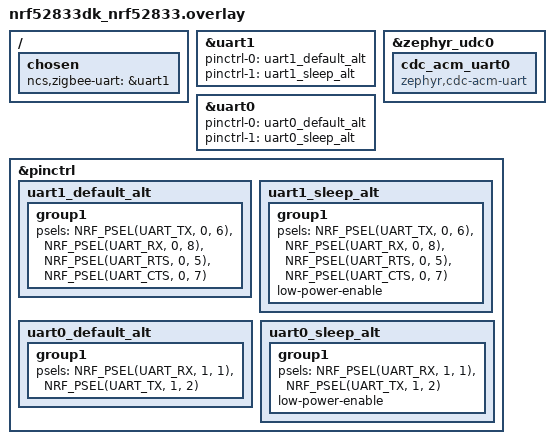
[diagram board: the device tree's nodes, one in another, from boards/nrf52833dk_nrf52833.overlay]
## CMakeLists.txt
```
#
# Copyright (c) 2024 Nordic Semiconductor ASA
#
# SPDX-License-Identifier: LicenseRef-Nordic-5-Clause
#

cmake_minimum_required(VERSION 3.20.0)

find_package(Zephyr REQUIRED HINTS $ENV{ZEPHYR_BASE})

project("ZBOSS NCP SoC firmware")

# NORDIC SDK APP START
target_sources(app PRIVATE
  src/main.c
  src/zboss_mem_globals.c
)
# NORDIC SDK APP END

if(CONFIG_LTO)
	set_source_files_properties(
		src/zboss_mem_globals.c
		PROPERTIES COMPILE_OPTIONS -fno-lto
	)
endif()
```

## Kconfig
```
#
# Copyright (c) 2025 Nordic Semiconductor ASA
#
# SPDX-License-Identifier: LicenseRef-Nordic-5-Clause
#

source "Kconfig.zephyr"

menuconfig ZIGBEE_NCP_USB
       bool "USB support for Zigbee NCP"
       select USB_DEVICE_STACK_NEXT
       select USBD_CDC_ACM_CLASS
       select UART_LINE_CTRL
       help
         Enable USB CDC ACM support for Zigbee NCP interface.
         This allows using the NCP over USB instead of UART.
         This uses the new USB device stack and is incompatible with
         the legacy USB_DEVICE_STACK option.

if ZIGBEE_NCP_USB

config ZIGBEE_NCP_USB_VID
       hex "USB Vendor ID"
       default 0x2fe3
       help
         USB Vendor ID for the Zigbee NCP device.
         Default uses Zephyr project VID (for samples only).

config ZIGBEE_NCP_USB_PID
       hex "USB Product ID"
       default 0x0001
       help
         USB Product ID for the Zigbee NCP device.

config ZIGBEE_NCP_USB_MAX_POWER
       int "USB device max power consumption (mA)"
       default 100
       range 2 500
       help
         Maximum power consumption of the USB device in milliamperes.

config ZIGBEE_NCP_USB_MANUFACTURER
       string "USB device manufacturer string"
       default "Nordic Semiconductor ASA"
       help
         USB device manufacturer string descriptor.

config ZIGBEE_NCP_USB_PRODUCT
       string "USB device product string"
       default "Zigbee NCP"
       help
         USB device product string descriptor.

endif # ZIGBEE_NCP_USB
```

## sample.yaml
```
# KRKNWK-22663: Twister scenarios are skipped while NCP libncp-dev libraries are
# not shipped. Builds fail at CMake with an explicit error.
sample:
  description: Zigbee network co-processor
  name: Zigbee NCP
common:
  tags:
    - ci_build
    - smoke
    - sysbuild
    - ci_samples_zigbee
tests:
  sample.zigbee.ncp:
    skip: true
    sysbuild: true
    build_only: true
    integration_platforms:
      - nrf52833dk/nrf52833
      - nrf52840dk/nrf52840
      - nrf54l15dk/nrf54l05/cpuapp
    platform_allow:
      - nrf52833dk/nrf52833
      - nrf52840dk/nrf52840
      - nrf5340dk/nrf5340/cpuapp
      - nrf54l15dk/nrf54l05/cpuapp
      - nrf54l15dk/nrf54l10/cpuapp
      - nrf54l15dk/nrf54l15/cpuapp
      - nrf54lm20dk/nrf54lm20a/cpuapp
      - nrf54lm20dk/nrf54lm20b/cpuapp
  sample.zigbee.ncp.usb:
    skip: true
    sysbuild: true
    build_only: true
    integration_platforms:
      - nrf52833dk/nrf52833
      - nrf52840dk/nrf52840
    platform_allow:
      - nrf52833dk/nrf52833
      - nrf52840dk/nrf52840
      - nrf5340dk/nrf5340/cpuapp
      - nrf54lm20dk/nrf54lm20a/cpuapp
      - nrf54lm20dk/nrf54lm20b/cpuapp
    extra_args:
      - FILE_SUFFIX=usb
  sample.zigbee.ncp.dongle:
    skip: true
    sysbuild: true
    build_only: true
    integration_platforms:
      - nrf52840dongle/nrf52840
    platform_allow:
      - nrf52840dongle/nrf52840
    extra_args:
      - FILE_SUFFIX=dongle
```

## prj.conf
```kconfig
#
# Copyright (c) 2024 Nordic Semiconductor ASA
#
# SPDX-License-Identifier: LicenseRef-Nordic-5-Clause
#

CONFIG_NCS_SAMPLES_DEFAULTS=y

CONFIG_ZIGBEE_ADD_ON=y

# Add libncp-dev library
CONFIG_ZIGBEE_LIBRARY_NCP_DEV=y

CONFIG_ZIGBEE_HAVE_SERIAL=y
CONFIG_ZIGBEE_HAVE_ASYNC_SERIAL=y
CONFIG_ZIGBEE_UART_RX_BUF_LEN=256
CONFIG_ZIGBEE_UART_TX_TIMEOUT=1000
CONFIG_ZIGBEE_UART_RX_TIMEOUT=1000

CONFIG_ZIGBEE_USE_LEDS=y
CONFIG_ZIGBEE_USE_BUTTONS=y
CONFIG_ZIGBEE_TIME_KTIMER=y

CONFIG_ZIGBEE_ROLE_COORDINATOR=y

CONFIG_HEAP_MEM_POOL_SIZE=2048

CONFIG_MAIN_THREAD_PRIORITY=7
# Networking
CONFIG_NET_IPV6=n
CONFIG_NET_IP_ADDR_CHECK=n
CONFIG_NET_UDP=n
```

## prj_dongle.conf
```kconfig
#
# Copyright (c) 2024 Nordic Semiconductor ASA
#
# SPDX-License-Identifier: LicenseRef-Nordic-5-Clause
#

# The NCP transport is a CDC ACM port, so the sample holds the stack until the host
# raises DTR. Boards turn line control on for their shell builds only.
CONFIG_UART_LINE_CTRL=y
CONFIG_ZIGBEE_UART_SUPPORTS_FLOW_CONTROL=y

# Configure NCP sample to print ZBOSS stack logs in binary format using uart1 device
# CONFIG_ZBOSS_TRACE_BINARY_LOGGING=y

#### Use this configuration to print ZBOSS stack logs in binary format using USB cdc_acm_uart1 device
# CONFIG_ZBOSS_TRACE_BINARY_LOGGING=y
# CONFIG_ZBOSS_TRACE_USB_CDC_LOGGING=y
# The second instance, cdc_acm_uart1, comes from the board overlay. See README.
####


# Use new USB stack with CDC ACM initialized at boot
CONFIG_USB_DEVICE_STACK_NEXT=y
CONFIG_CDC_ACM_SERIAL_INITIALIZE_AT_BOOT=y
CONFIG_CDC_ACM_SERIAL_VID=0x1915
CONFIG_CDC_ACM_SERIAL_PID=0x0001
CONFIG_CDC_ACM_SERIAL_MANUFACTURER_STRING="Nordic Semiconductor ASA"
CONFIG_CDC_ACM_SERIAL_PRODUCT_STRING="Zigbee NCP"

CONFIG_USBD_LOG_LEVEL_WRN=y
CONFIG_UDC_DRIVER_LOG_LEVEL_WRN=y
CONFIG_USBD_CDC_ACM_LOG_LEVEL_ERR=y

# Those settings below are common with prj.conf

CONFIG_NCS_SAMPLES_DEFAULTS=y

CONFIG_ZIGBEE_ADD_ON=y

# Add libncp-dev library
CONFIG_ZIGBEE_LIBRARY_NCP_DEV=y

CONFIG_ZIGBEE_HAVE_SERIAL=y
CONFIG_ZIGBEE_HAVE_ASYNC_SERIAL=y
CONFIG_ZIGBEE_UART_RX_BUF_LEN=256
CONFIG_ZIGBEE_UART_TX_TIMEOUT=1000
CONFIG_ZIGBEE_UART_RX_TIMEOUT=1000

CONFIG_ZIGBEE_USE_LEDS=y
CONFIG_ZIGBEE_USE_BUTTONS=y
CONFIG_ZIGBEE_TIME_KTIMER=y

CONFIG_ZIGBEE_ROLE_COORDINATOR=y

CONFIG_HEAP_MEM_POOL_SIZE=2048

CONFIG_MAIN_THREAD_PRIORITY=7
# Networking
CONFIG_NET_IPV6=n
CONFIG_NET_IP_ADDR_CHECK=n
CONFIG_NET_UDP=n
```

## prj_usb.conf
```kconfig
#
# Copyright (c) 2021 Nordic Semiconductor ASA
#
# SPDX-License-Identifier: LicenseRef-Nordic-5-Clause
#

# The NCP transport is a CDC ACM port, so the sample holds the stack until the host
# raises DTR. Boards turn line control on for their shell builds only.
CONFIG_UART_LINE_CTRL=y
CONFIG_ZIGBEE_UART_SUPPORTS_FLOW_CONTROL=y

# Configure NCP sample to print ZBOSS stack logs in binary format using uart1 device
# CONFIG_ZBOSS_TRACE_BINARY_LOGGING=y

#### Use this configuration to print ZBOSS stack logs in binary format using USB cdc_acm_uart1 device
# CONFIG_ZBOSS_TRACE_BINARY_LOGGING=y
# CONFIG_ZBOSS_TRACE_USB_CDC_LOGGING=y
# The second instance, cdc_acm_uart1, comes from the board overlay. See README.
####

# Use new USB stack with CDC ACM initialized at boot
CONFIG_USB_DEVICE_STACK_NEXT=y
CONFIG_CDC_ACM_SERIAL_INITIALIZE_AT_BOOT=y
CONFIG_CDC_ACM_SERIAL_VID=0x1915
CONFIG_CDC_ACM_SERIAL_PID=0x0001
CONFIG_CDC_ACM_SERIAL_MANUFACTURER_STRING="Nordic Semiconductor ASA"
CONFIG_CDC_ACM_SERIAL_PRODUCT_STRING="Zigbee NCP"

CONFIG_USBD_LOG_LEVEL_WRN=y
CONFIG_UDC_DRIVER_LOG_LEVEL_WRN=y
CONFIG_USBD_CDC_ACM_LOG_LEVEL_ERR=y

# Those settings below are common with prj.conf

CONFIG_NCS_SAMPLES_DEFAULTS=y

CONFIG_ZIGBEE_ADD_ON=y

# Add libncp-dev library
CONFIG_ZIGBEE_LIBRARY_NCP_DEV=y

CONFIG_ZIGBEE_HAVE_SERIAL=y
CONFIG_ZIGBEE_HAVE_ASYNC_SERIAL=y
CONFIG_ZIGBEE_UART_RX_BUF_LEN=256
CONFIG_ZIGBEE_UART_TX_TIMEOUT=1000
CONFIG_ZIGBEE_UART_RX_TIMEOUT=1000

CONFIG_ZIGBEE_USE_LEDS=y
CONFIG_ZIGBEE_USE_BUTTONS=y
CONFIG_ZIGBEE_TIME_KTIMER=y

CONFIG_ZIGBEE_ROLE_COORDINATOR=y

CONFIG_HEAP_MEM_POOL_SIZE=2048

CONFIG_MAIN_THREAD_PRIORITY=7
# Networking
CONFIG_NET_IPV6=n
CONFIG_NET_IP_ADDR_CHECK=n
CONFIG_NET_UDP=n
```

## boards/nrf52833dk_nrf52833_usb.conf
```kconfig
#
# Copyright (c) 2026 Nordic Semiconductor ASA
#
# SPDX-License-Identifier: LicenseRef-Nordic-5-Clause
#

# Enable MCUBoot
CONFIG_BOOTLOADER_MCUBOOT=y
```

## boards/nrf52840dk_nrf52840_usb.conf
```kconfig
#
# Copyright (c) 2025 Nordic Semiconductor ASA
#
# SPDX-License-Identifier: LicenseRef-Nordic-5-Clause
#

# Enable MCUBoot
CONFIG_BOOTLOADER_MCUBOOT=y

# Enable nRF ECB driver
CONFIG_CRYPTO=y
CONFIG_CRYPTO_NRF_ECB=y
CONFIG_CRYPTO_INIT_PRIORITY=80
```

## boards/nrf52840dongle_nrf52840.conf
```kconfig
#
# Copyright (c) 2025 Nordic Semiconductor ASA
#
# SPDX-License-Identifier: LicenseRef-Nordic-5-Clause
#

# Inform application that CDC ACM requires the line control signals to be configured.
CONFIG_ZIGBEE_UART_SUPPORTS_FLOW_CONTROL=y

# Configure NCP sample to print ZBOSS stack logs in binary format using uart1 device
# CONFIG_ZBOSS_TRACE_BINARY_LOGGING=y

#### Use this configuration to print ZBOSS stack logs in binary format using USB cdc_acm_uart1 device
# CONFIG_ZBOSS_TRACE_BINARY_LOGGING=y
# CONFIG_ZBOSS_TRACE_USB_CDC_LOGGING=y
# The second instance, cdc_acm_uart1, comes from the board overlay. See README.
####
```

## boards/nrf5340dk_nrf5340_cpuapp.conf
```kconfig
#
# Copyright (c) 2025 Nordic Semiconductor ASA
#
# SPDX-License-Identifier: LicenseRef-Nordic-5-Clause
#

CONFIG_NRF53_UPGRADE_NETWORK_CORE=n
```

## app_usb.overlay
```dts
/*
 * Copyright (c) 2026 Nordic Semiconductor ASA
 *
 * SPDX-License-Identifier: LicenseRef-Nordic-5-Clause
 */

&zephyr_udc0 {
	cdc_acm_uart0: cdc_acm_uart {
		compatible = "zephyr,cdc-acm-uart";
	};
};

/ {
	chosen {
		ncs,zigbee-uart = &cdc_acm_uart0;
	};
};
```

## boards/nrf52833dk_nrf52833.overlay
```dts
/*
 * Copyright (c) 2026 Nordic Semiconductor ASA
 *
 * SPDX-License-Identifier: LicenseRef-Nordic-5-Clause
 */

#include <nrf52833_partitions.dtsi>

&uart1 {
	status = "okay";
	pinctrl-0 = <&uart1_default_alt>;
	pinctrl-1 = <&uart1_sleep_alt>;
	pinctrl-names = "default", "sleep";
};

&uart0 {
	pinctrl-0 = <&uart0_default_alt>;
	pinctrl-1 = <&uart0_sleep_alt>;
	pinctrl-names = "default", "sleep";
};

&zephyr_udc0 {
	cdc_acm_uart0: cdc_acm_uart0 {
		compatible = "zephyr,cdc-acm-uart";
	};
};

&pinctrl {
	uart1_default_alt: uart1_default_alt {
		group1 {
			psels = <NRF_PSEL(UART_TX, 0, 6)>,
				<NRF_PSEL(UART_RX, 0, 8)>,
				<NRF_PSEL(UART_RTS, 0, 5)>,
				<NRF_PSEL(UART_CTS, 0, 7)>;
		};
	};

	uart1_sleep_alt: uart1_sleep_alt {
		group1 {
			psels = <NRF_PSEL(UART_TX, 0, 6)>,
				<NRF_PSEL(UART_RX, 0, 8)>,
				<NRF_PSEL(UART_RTS, 0, 5)>,
				<NRF_PSEL(UART_CTS, 0, 7)>;
			low-power-enable;
		};
	};

	uart0_default_alt: uart0_default_alt {
		group1 {
			psels = <NRF_PSEL(UART_RX, 1, 1)>,
				<NRF_PSEL(UART_TX, 1, 2)>;
		};
	};

	uart0_sleep_alt: uart0_sleep_alt {
		group1 {
			psels = <NRF_PSEL(UART_RX, 1, 1)>,
				<NRF_PSEL(UART_TX, 1, 2)>;
			low-power-enable;
		};
	};
};

/ {
	chosen {
		ncs,zigbee-uart = &uart1;
	};
};
```

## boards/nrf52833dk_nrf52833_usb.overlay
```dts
/*
 * Copyright (c) 2026 Nordic Semiconductor ASA
 *
 * SPDX-License-Identifier: LicenseRef-Nordic-5-Clause
 */

#include <nrf52833_partitions.dtsi>
#include <mcuboot_usb_transport/nrf52833_partitions.dtsi>

&zephyr_udc0 {
	cdc_acm_uart0: cdc_acm_uart0 {
		compatible = "zephyr,cdc-acm-uart";
	};
};

/ {
	chosen {
		ncs,zigbee-uart = &cdc_acm_uart0;
	};
};
```

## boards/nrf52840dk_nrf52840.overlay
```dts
/*
 * Copyright (c) 2025 Nordic Semiconductor ASA
 *
 * SPDX-License-Identifier: LicenseRef-Nordic-5-Clause
 */

#include <nrf52840_partitions.dtsi>

&uart1 {
	pinctrl-0 = <&uart1_default_alt>;
	pinctrl-1 = <&uart1_sleep_alt>;
	pinctrl-names = "default", "sleep";
	status = "okay";
};

&uart0 {
	pinctrl-0 = <&uart0_default_alt>;
	pinctrl-1 = <&uart0_sleep_alt>;
	pinctrl-names = "default", "sleep";
};

&zephyr_udc0 {
	cdc_acm_uart0: cdc_acm_uart0 {
		compatible = "zephyr,cdc-acm-uart";
	};
};

&pinctrl {
	uart1_default_alt: uart1_default_alt {
		group1 {
			psels = <NRF_PSEL(UART_TX, 0, 6)>,
				<NRF_PSEL(UART_RX, 0, 8)>,
				<NRF_PSEL(UART_RTS, 0, 5)>,
				<NRF_PSEL(UART_CTS, 0, 7)>;
		};
	};

	uart1_sleep_alt: uart1_sleep_alt {
		group1 {
			psels = <NRF_PSEL(UART_TX, 0, 6)>,
				<NRF_PSEL(UART_RX, 0, 8)>,
				<NRF_PSEL(UART_RTS, 0, 5)>,
				<NRF_PSEL(UART_CTS, 0, 7)>;
			low-power-enable;
		};
	};

	uart0_default_alt: uart0_default_alt {
		group1 {
			psels = <NRF_PSEL(UART_RX, 1, 1)>,
				<NRF_PSEL(UART_TX, 1, 2)>;
		};
	};

	uart0_sleep_alt: uart0_sleep_alt {
		group1 {
			psels = <NRF_PSEL(UART_RX, 1, 1)>,
				<NRF_PSEL(UART_TX, 1, 2)>;
			low-power-enable;
		};
	};
};

/ {
	chosen {
		ncs,zigbee-uart = &uart1;
	};
};
```

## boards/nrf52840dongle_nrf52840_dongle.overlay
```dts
/*
 * Copyright (c) 2025 Nordic Semiconductor ASA
 *
 * SPDX-License-Identifier: LicenseRef-Nordic-5-Clause
 */

#include <nrf52840dongle_partitions.dtsi>

/ {
	chosen {
		ncs,zigbee-uart = &board_cdc_acm_uart;
	};

	buttons {
		compatible = "gpio-keys";

		rst_button0: rst_button_0 {
			gpios = <&gpio0 19 (GPIO_PULL_UP | GPIO_ACTIVE_LOW)>;
			label = "Reset button";
		};
	};

	aliases {
		rst0 = &rst_button0;
	};
};
```

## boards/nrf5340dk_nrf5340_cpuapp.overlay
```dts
/*
 * Copyright (c) 2025 Nordic Semiconductor ASA
 *
 * SPDX-License-Identifier: LicenseRef-Nordic-5-Clause
 */

#include <nrf5340_cpuapp_partitions.dtsi>

&uart1 {
	status = "okay";
	pinctrl-0 = <&uart1_default_alt>;
	pinctrl-1 = <&uart1_sleep_alt>;
	pinctrl-names = "default", "sleep";
};

&uart0 {
	pinctrl-0 = <&uart0_default_alt>;
	pinctrl-1 = <&uart0_sleep_alt>;
	pinctrl-names = "default", "sleep";
};

/ {
	chosen {
		ncs,zigbee-uart = &uart1;
	};
};

&pinctrl {
	uart1_default_alt: uart1_default_alt {
		group1 {
			psels = <NRF_PSEL(UART_TX, 0, 20)>,
				<NRF_PSEL(UART_RX, 0, 22)>,
				<NRF_PSEL(UART_RTS, 0, 19)>,
				<NRF_PSEL(UART_CTS, 0, 21)>;
		};
	};

	uart1_sleep_alt: uart1_sleep_alt {
		group1 {
			psels = <NRF_PSEL(UART_TX, 0, 20)>,
				<NRF_PSEL(UART_RX, 0, 22)>,
				<NRF_PSEL(UART_RTS, 0, 19)>,
				<NRF_PSEL(UART_CTS, 0, 21)>;
			low-power-enable;
		};
	};

	uart0_default_alt: uart0_default_alt {
		group1 {
			psels = <NRF_PSEL(UART_RX, 1, 4)>,
				<NRF_PSEL(UART_TX, 1, 5)>;
		};
	};

	uart0_sleep_alt: uart0_sleep_alt {
		group1 {
			psels = <NRF_PSEL(UART_RX, 1, 4)>,
				<NRF_PSEL(UART_TX, 1, 5)>;
			low-power-enable;
		};
	};
};
```

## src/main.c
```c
/*
 * Copyright (c) 2024 Nordic Semiconductor ASA
 *
 * SPDX-License-Identifier: LicenseRef-Nordic-5-Clause
 */

/** @file
 *  @brief Zigbee Network Co-processor sample
 */

#include <zephyr/drivers/uart.h>
#include <zephyr/drivers/gpio.h>
#include <zephyr/logging/log.h>
#include <zb_nrf_platform.h>
#include <zb_led_button.h>
#include <zb_osif_ext.h>
#include <zephyr/kernel.h>
#include <zephyr/device.h>
#include <dk_buttons_and_leds.h>
#include <ncp/ncp_dev_api.h>

#if CONFIG_BOOTLOADER_MCUBOOT
#include <zephyr/dfu/mcuboot.h>
#endif

LOG_MODULE_REGISTER(app, LOG_LEVEL_INF);

#define VENDOR_SPECIFIC_LED DK_LED2

#define VENDOR_SPECIFIC_LED_ACTION_OFF (0U)
#define VENDOR_SPECIFIC_LED_ACTION_ON (1U)
#define VENDOR_SPECIFIC_LED_ACTION_TOGGLE (2U)

#define VENDOR_SPECIFIC_REQUEST_LEN (1U)
#define VENDOR_SPECIFIC_RESPONSE_LEN (1U)

#define VENDOR_SPECIFIC_IND_LEN (1U)
#define VENDOR_SPECIFIC_IND_DELAY (ZB_TIME_ONE_SECOND * 3)

#define DTR_POLL_INTERVAL_MS (100U)
#define HOST_SETTLE_TIME_MS (1000U)


/* The state of a led controlled by ncp custom commands */
static zb_uint8_t vendor_specific_led_state = VENDOR_SPECIFIC_LED_ACTION_OFF;


zb_ret_t zb_osif_bootloader_run_after_reboot(void)
{
#if DT_NODE_EXISTS(DT_ALIAS(rst0))
	int err = 0;
	const struct gpio_dt_spec rst0 = GPIO_DT_SPEC_GET(DT_ALIAS(rst0), gpios);

	if (!device_is_ready(rst0.port)) {
		return RET_ERROR;
	}

	err = gpio_pin_configure_dt(&rst0, GPIO_OUTPUT_ACTIVE);
	if (err) {
		return RET_ERROR;
	}
#endif
	return RET_OK;
}

void zb_osif_bootloader_report_successful_loading(void)
{
#if CONFIG_BOOTLOADER_MCUBOOT
	if (!boot_is_img_confirmed()) {
		int ret = boot_write_img_confirmed();

		if (ret) {
			LOG_ERR("Couldn't confirm image: %d", ret);
		} else {
			LOG_INF("Marked image as OK");
		}
	}
#endif
}

static void custom_indication(zb_cb_param_t cb_param)
{
	zb_bufid_t buf = ZB_UNPACK_BUF_REF(cb_param);
	zb_uint16_t led_idx = ZB_UNPACK_USER_PARAM(cb_param);

	if (!buf) {
		zb_buf_get_out_delayed_ext(custom_indication, led_idx, 0);
		return;
	}

	zb_uint8_t *ind_data = zb_buf_initial_alloc(buf, VENDOR_SPECIFIC_IND_LEN);

	*ind_data = (zb_uint8_t)led_idx;

	zb_ncp_custom_indication(buf);
}

static void perform_custom_indication(zb_cb_param_t led_idx)
{
	zb_buf_get_out_delayed_ext(custom_indication, (zb_uint16_t)led_idx, 0);
}

#if (defined ZBOSS_PLATFORM_MAJOR) && (ZBOSS_PLATFORM_MAJOR < 5U)
static zb_ret_t ncp_vendor_specific_req_handler(zb_bufid_t buf)
#else /* (defined ZBOSS_PLATFORM_MAJOR) && (ZBOSS_PLATFORM_MAJOR < 5U) */
static zb_uint16_t ncp_vendor_specific_req_handler(zb_bufid_t buf)
#endif /* (defined ZBOSS_PLATFORM_MAJOR) && (ZBOSS_PLATFORM_MAJOR < 5U) */
{
	/* request tsn */
	zb_uint8_t tsn = *ZB_BUF_GET_PARAM(buf, zb_uint8_t);
	/* actual payload passed by the request */
	zb_uint8_t *led_action = (zb_uint8_t *)zb_buf_begin(buf);

	zb_uint8_t resp_buf = zb_buf_get(ZB_FALSE, VENDOR_SPECIFIC_RESPONSE_LEN);
	zb_uint8_t *resp_data;
	ncp_hl_custom_resp_t *resp_args;

	if (resp_buf == ZB_BUF_INVALID) {
		LOG_ERR("Couldn't get buf");
		return RET_NO_MEMORY;
	}

	resp_data = zb_buf_initial_alloc(resp_buf, VENDOR_SPECIFIC_RESPONSE_LEN);
	resp_args = ZB_BUF_GET_PARAM(resp_buf, ncp_hl_custom_resp_t);

	if (zb_buf_len(buf) == VENDOR_SPECIFIC_REQUEST_LEN) {
		switch (*led_action) {
		case VENDOR_SPECIFIC_LED_ACTION_OFF:
			zb_osif_led_off(VENDOR_SPECIFIC_LED);
			resp_args->status = RET_OK;

			vendor_specific_led_state = 0;
			break;
		case VENDOR_SPECIFIC_LED_ACTION_ON:
			zb_osif_led_on(VENDOR_SPECIFIC_LED);
			resp_args->status = RET_OK;

			vendor_specific_led_state = 1;
			break;
		case VENDOR_SPECIFIC_LED_ACTION_TOGGLE:
			vendor_specific_led_state ^= 0x01;
			if (vendor_specific_led_state) {
				zb_osif_led_on(VENDOR_SPECIFIC_LED);
			} else {
				zb_osif_led_off(VENDOR_SPECIFIC_LED);
			}
			resp_args->status = RET_OK;

			break;
		default:
			resp_args->status = RET_ERROR;
			break;
		}
	} else {
		resp_args->status = RET_ERROR;
	}

	resp_args->tsn = tsn;
	*resp_data = vendor_specific_led_state;
	ZVUNUSED(zb_ncp_custom_response(resp_buf));

	return NCP_RET_LATER;
}

static void ncp_vendor_specific_init(void)
{
	zb_osif_led_button_init();

	zb_ncp_custom_register_request_cb(ncp_vendor_specific_req_handler);

	ZB_SCHEDULE_APP_ALARM(perform_custom_indication, (zb_uint8_t)VENDOR_SPECIFIC_LED,
						  VENDOR_SPECIFIC_IND_DELAY);
}

#if CONFIG_ZIGBEE_UART_SUPPORTS_FLOW_CONTROL
/* Hold the stack back until the host has opened the NCP port.
 *
 * A co-processor whose transport is a CDC ACM port has nowhere to send until then, and the
 * sample starts talking on its own as soon as its custom indication alarm expires, so
 * starting earlier only spends that exchange on a port nobody is reading.
 */
static int wait_for_host(void)
{
	const struct device *uart_dev = DEVICE_DT_GET(DT_CHOSEN(ncs_zigbee_uart));
	uint32_t dtr = 0U;

	if (!device_is_ready(uart_dev)) {
		LOG_ERR("NCP UART device not ready");
		return -ENODEV;
	}

	while (!dtr) {
		if (uart_line_ctrl_get(uart_dev, UART_LINE_CTRL_DTR, &dtr)) {
			LOG_ERR("Couldn't read DTR, continuing without waiting for the host");
			return 0;
		}
		k_sleep(K_MSEC(DTR_POLL_INTERVAL_MS));
	}

	(void)uart_line_ctrl_set(uart_dev, UART_LINE_CTRL_DCD, 1);
	(void)uart_line_ctrl_set(uart_dev, UART_LINE_CTRL_DSR, 1);

	k_sleep(K_MSEC(HOST_SETTLE_TIME_MS));

	return 0;
}
#else
static int wait_for_host(void)
{
	return 0;
}
#endif /* CONFIG_ZIGBEE_UART_SUPPORTS_FLOW_CONTROL */

int main(void)
{
	int err;

	LOG_INF("Starting Zigbee R23 Network Co-processor application");

	zb_osif_ncp_set_nvram_filter();

	err = wait_for_host();
	if (err) {
		return err;
	}

	/* Setup ncp custom command handling */
	ncp_vendor_specific_init();

	/* Start Zigbee default thread */
	zigbee_enable();

	LOG_INF("Zigbee R23 Network Co-processor application started");

	return 0;
}
```
